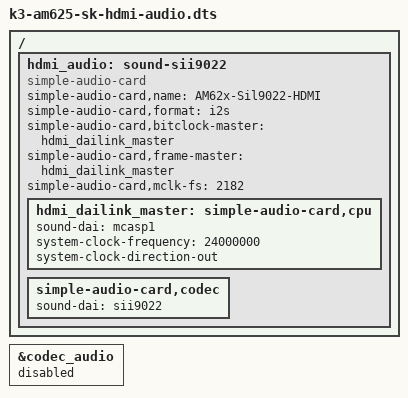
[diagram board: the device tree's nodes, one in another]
// SPDX-License-Identifier: GPL-2.0
/**
 * Audio playback via HDMI
 *
 * Copyright (C) 2022 Texas Instruments Incorporated - http://www.ti.com/
 */

/dts-v1/;
/plugin/;

/ {
	fragment@101 {
		target-path = "/";

		__overlay__ {
			hdmi_audio: sound-sii9022 {
				compatible = "simple-audio-card";
				simple-audio-card,name = "AM62x-Sil9022-HDMI";
				simple-audio-card,format = "i2s";
				simple-audio-card,bitclock-master = <&hdmi_dailink_master>;
				simple-audio-card,frame-master = <&hdmi_dailink_master>;
				simple-audio-card,mclk-fs = <2182>;

				hdmi_dailink_master: simple-audio-card,cpu {
					sound-dai = <&mcasp1>;
					system-clock-frequency = <24000000>;
					system-clock-direction-out;
				};

				simple-audio-card,codec {
					sound-dai = <&sii9022>;
				};
			};
		};
	};
};

&codec_audio {
	status = "disabled";
};
